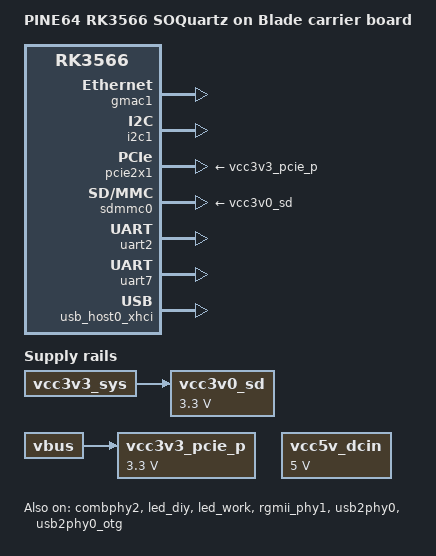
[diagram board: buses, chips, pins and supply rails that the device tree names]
/dts-v1/;
#include <dt-bindings/gpio/gpio.h>
#include <dt-bindings/input/input.h>
#include <dt-bindings/leds/common.h>
#include <dt-bindings/pinctrl/rockchip.h>
#include "rk3566-soquartz.dtsi"
/ {
	model = "PINE64 RK3566 SOQuartz on Blade carrier board";
	compatible = "pine64,soquartz-blade", "pine64,soquartz", "rockchip,rk3566";
	vcc3v0_sd: vcc3v0-sd-regulator {
		compatible = "regulator-fixed";
		regulator-name = "vcc3v0_sd";
		regulator-always-on;
		regulator-boot-on;
		regulator-min-microvolt = <3300000>;
		regulator-max-microvolt = <3300000>;
		vin-supply = <&vcc3v3_sys>;
	};
	vcc3v3_pcie_p: vcc3v3-pcie-regulator {
		compatible = "regulator-fixed";
		regulator-name = "vcc3v3_pcie_p";
		regulator-always-on;
		regulator-boot-on;
		regulator-min-microvolt = <3300000>;
		regulator-max-microvolt = <3300000>;
		vin-supply = <&vbus>;
	};
	vcc5v_dcin: vcc5v-dcin-regulator {
		compatible = "regulator-fixed";
		regulator-name = "vcc5v_dcin";
		regulator-always-on;
		regulator-boot-on;
		regulator-min-microvolt = <5000000>;
		regulator-max-microvolt = <5000000>;
	};
};
&combphy2 {
	phy-supply = <&vcc3v3_sys>;
	status = "okay";
};
&gmac1 {
	status = "okay";
};
&i2c1 {
	status = "okay";
};
&i2c2 {
	status = "disabled";
};
&i2c3 {
	status = "disabled";
};
&i2c4 {
	status = "disabled";
};
&i2s1_8ch {
	status = "disabled";
};
&led_diy {
	color = <LED_COLOR_ID_RED>;
	function = LED_FUNCTION_DISK_ACTIVITY;
	linux,default-trigger = "disk-activity";
	status = "okay";
};
&led_work {
	color = <LED_COLOR_ID_GREEN>;
	function = LED_FUNCTION_STATUS;
	linux,default-trigger = "heartbeat";
	status = "okay";
};
&pcie2x1 {
	vpcie3v3-supply = <&vcc3v3_pcie_p>;
	status = "okay";
};
&rgmii_phy1 {
	status = "okay";
};
&saradc {
	status = "disabled";
};
&sdmmc0 {
	vmmc-supply = <&vcc3v0_sd>;
	status = "okay";
};
&spi3 {
	status = "disabled";
};
&uart2 {
	status = "okay";
};
&uart7 {
	status = "okay";
};
&usb2phy0 {
	status = "okay";
};
&usb2phy0_otg {
	phy-supply = <&vbus>;
	status = "okay";
};
&usb_host0_xhci {
	status = "okay";
};
&vbus {
	vin-supply = <&vcc5v_dcin>;
};
